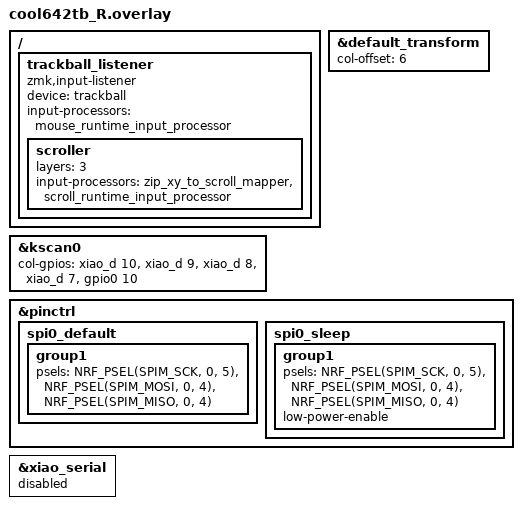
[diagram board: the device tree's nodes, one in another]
#include "cool642tb.dtsi"
#include <input/processors.dtsi>
#include <input/processors/runtime-input-processor.dtsi>
#include <behaviors/battery_history_request.dtsi>

&default_transform {
    col-offset = <6>;
};

&kscan0 {
        col-gpios
            = <&xiao_d 10 GPIO_ACTIVE_HIGH>
            , <&xiao_d 9 GPIO_ACTIVE_HIGH> 
            , <&xiao_d 8 GPIO_ACTIVE_HIGH> 
            , <&xiao_d 7 GPIO_ACTIVE_HIGH> 
            , <&gpio0 10 GPIO_ACTIVE_HIGH>
            ;
};


&pinctrl {
    spi0_default: spi0_default {
        group1 {
            psels = <NRF_PSEL(SPIM_SCK, 0, 5)>,
                <NRF_PSEL(SPIM_MOSI, 0, 4)>,
                <NRF_PSEL(SPIM_MISO, 0, 4)>;
        };
    };

    spi0_sleep: spi0_sleep {
        group1 {
            psels = <NRF_PSEL(SPIM_SCK, 0, 5)>,
                <NRF_PSEL(SPIM_MOSI, 0, 4)>,
                <NRF_PSEL(SPIM_MISO, 0, 4)>;
            low-power-enable;
        };
    };
};

&xiao_serial { status = "disabled"; };
/ {
    trackball_listener: trackball_listener {
        compatible = "zmk,input-listener";
        device = <&trackball>;
        input-processors = <&mouse_runtime_input_processor>;

        /* Layer 3 (ARROW): convert cursor movement to scroll */
        scroller {
            layers = <3>;
            input-processors = <&zip_xy_to_scroll_mapper &scroll_runtime_input_processor>;
        };
    };
};
